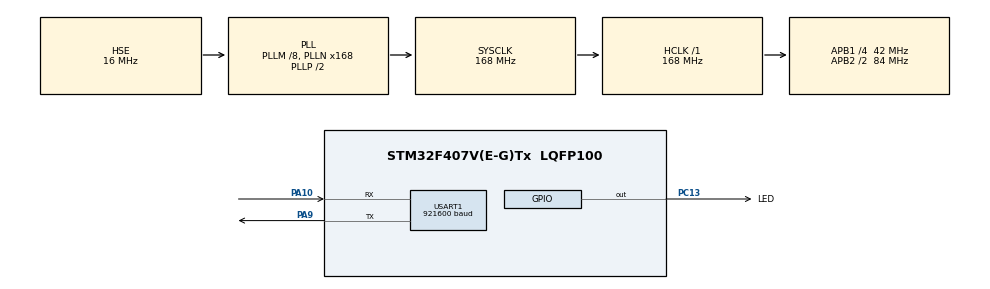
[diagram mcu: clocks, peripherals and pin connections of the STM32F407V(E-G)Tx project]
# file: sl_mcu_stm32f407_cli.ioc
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Dma.Request0=USART1_RX
Dma.Request1=USART1_TX
Dma.USART1_RX.0.Direction=DMA_PERIPH_TO_MEMORY
Dma.USART1_RX.0.FIFOMode=DMA_FIFOMODE_DISABLE
Dma.USART1_RX.0.Instance=DMA2_Stream2
Dma.USART1_RX.0.MemDataAlignment=DMA_MDATAALIGN_BYTE
Dma.USART1_RX.0.MemInc=DMA_MINC_ENABLE
Dma.USART1_RX.0.Mode=DMA_CIRCULAR
Dma.USART1_RX.0.PeriphDataAlignment=DMA_PDATAALIGN_BYTE
Dma.USART1_RX.0.PeriphInc=DMA_PINC_DISABLE
Dma.USART1_RX.0.Priority=DMA_PRIORITY_LOW
Dma.USART1_TX.1.Direction=DMA_MEMORY_TO_PERIPH
Dma.USART1_TX.1.FIFOMode=DMA_FIFOMODE_DISABLE
Dma.USART1_TX.1.Instance=DMA2_Stream7
Dma.USART1_TX.1.MemDataAlignment=DMA_MDATAALIGN_BYTE
Dma.USART1_TX.1.MemInc=DMA_MINC_ENABLE
Dma.USART1_TX.1.Mode=DMA_CIRCULAR
Dma.USART1_TX.1.PeriphDataAlignment=DMA_PDATAALIGN_BYTE
Dma.USART1_TX.1.PeriphInc=DMA_PINC_DISABLE
Dma.USART1_TX.1.Priority=DMA_PRIORITY_LOW
Mcu.Family=STM32F4
Mcu.Name=STM32F407V(E-G)Tx
Mcu.Package=LQFP100
NVIC.DMA2_Stream2_IRQn=true\:0\:0\:false\:false\:true\:false\:true\:true
NVIC.DMA2_Stream7_IRQn=true\:0\:0\:false\:false\:true\:false\:true\:true
NVIC.PriorityGroup=NVIC_PRIORITYGROUP_4
NVIC.USART1_IRQn=true\:0\:0\:false\:false\:true\:true\:true\:true
PA10.Mode=Asynchronous
PA10.Signal=USART1_RX
PA13.Mode=Trace_Asynchronous_SW
PA13.Signal=SYS_JTMS-SWDIO
PA14.Mode=Trace_Asynchronous_SW
PA14.Signal=SYS_JTCK-SWCLK
PA9.Mode=Asynchronous
PA9.Signal=USART1_TX
PB3.Mode=Trace_Asynchronous_SW
PB3.Signal=SYS_JTDO-SWO
PC13-ANTI_TAMP.GPIO_Label=LED
PC13-ANTI_TAMP.GPIO_ModeDefaultOutputPP=GPIO_MODE_OUTPUT_OD
PC13-ANTI_TAMP.GPIO_PuPd=GPIO_NOPULL
PC13-ANTI_TAMP.PinState=GPIO_PIN_SET
PC13-ANTI_TAMP.Signal=GPIO_Output
PH0-OSC_IN.Mode=HSE-External-Oscillator
PH0-OSC_IN.Signal=RCC_OSC_IN
PH1-OSC_OUT.Mode=HSE-External-Oscillator
PH1-OSC_OUT.Signal=RCC_OSC_OUT
ProjectManager.HeapSize=0x200
ProjectManager.StackSize=0x400
ProjectManager.TargetToolchain=STM32CubeIDE
RCC.48MHZClocksFreq_Value=48000000
RCC.AHBFreq_Value=168000000
RCC.APB1CLKDivider=RCC_HCLK_DIV4
RCC.APB1Freq_Value=42000000
RCC.APB1TimFreq_Value=84000000
RCC.APB2CLKDivider=RCC_HCLK_DIV2
RCC.APB2Freq_Value=84000000
RCC.APB2TimFreq_Value=168000000
RCC.CortexFreq_Value=168000000
RCC.HCLKFreq_Value=168000000
RCC.HSE_VALUE=16000000
RCC.HSI_VALUE=16000000
RCC.LSE_VALUE=32768
RCC.PLLM=8
RCC.PLLN=168
RCC.PLLQ=7
RCC.PLLSourceVirtual=RCC_PLLSOURCE_HSE
RCC.SYSCLKFreq_VALUE=168000000
RCC.SYSCLKSource=RCC_SYSCLKSOURCE_PLLCLK
RCC.VCOOutputFreq_Value=336000000
USART1.BaudRate=921600
USART1.OverSampling=UART_OVERSAMPLING_8
USART1.VirtualMode=VM_ASYNC
board=custom

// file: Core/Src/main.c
/* USER CODE BEGIN Header */
/**
 ******************************************************************************
 * @file           : main.c
 * @brief          : Main program body
 ******************************************************************************
 * @attention
 *
 * Copyright (c) 2026 STM32World <lth@stm32world.com>
 * All rights reserved.
 *
 * This software is licensed under terms that can be found in the LICENSE file
 * in the root directory of this software component.
 * If no LICENSE file comes with this software, it is provided AS-IS.
 *
 ******************************************************************************
 */
/* USER CODE END Header */
#include "main.h"

/* USER CODE BEGIN Includes */
#include <stdio.h>

// Just include the header here; DO NOT define EMBEDDED_CLI_IMPL here
#include "embedded_cli.h"
/* USER CODE END Includes */

/* USER CODE BEGIN PD */
#define RX_BUFFER_SIZE 128
/* USER CODE END PD */

UART_HandleTypeDef huart1;
DMA_HandleTypeDef hdma_usart1_rx;
DMA_HandleTypeDef hdma_usart1_tx;

/* USER CODE BEGIN PV */
EmbeddedCli *cli = NULL;
uint8_t rx_dma_buffer[RX_BUFFER_SIZE];
uint16_t old_pos = 0;
/* USER CODE END PV */

void SystemClock_Config(void);
static void MX_GPIO_Init(void);
static void MX_DMA_Init(void);
static void MX_USART1_UART_Init(void);
/* USER CODE BEGIN PFP */
void init_console(void);
void process_uart_dma_input(void);
/* USER CODE END PFP */

/* USER CODE BEGIN 0 */

// Send printf to uart1
int __io_putchar(int ch) {
    if (ch == '\n') {
        HAL_UART_Transmit(&huart1, (uint8_t*) "\r", 1, HAL_MAX_DELAY);
    }
    if (HAL_UART_Transmit(&huart1, (uint8_t*) &ch, 1, HAL_MAX_DELAY) != HAL_OK) {
        return -1;
    }
    return ch;
}

// 1. Provide a physical write wrapper (UART DMA / IT)
void write_char_cb(EmbeddedCli *cli, char c) {
    HAL_UART_Transmit(&huart1, (uint8_t*) &c, 1, HAL_MAX_DELAY);
}

// 2. Define a callback function for a command
void on_led_command(EmbeddedCli *cli, char *args, void *context) {
    HAL_GPIO_TogglePin(LED_GPIO_Port, LED_Pin);
    embeddedCliPrint(cli, "LED Toggled!\r\n");
}

void init_console(void) {
    // 3. Initialize CLI with default settings
    EmbeddedCliConfig *config = embeddedCliDefaultConfig();
    config->maxBindingCount = 16;
    cli = embeddedCliNew(config);
    if (cli == NULL) return;

    cli->writeChar = write_char_cb;

    // 4. Bind a command
    embeddedCliAddBinding(cli, (CliCommandBinding ) {
                    .name = "toggle-led",
                    .help = "Toggles the onboard LED",
                    .tokenizeArgs = false,
                    .context = NULL,
                    .binding = on_led_command
            });

    // 5. Start RX DMA & IDLE Line Interrupt
    __HAL_UART_ENABLE_IT(&huart1, UART_IT_IDLE);
    HAL_UART_Receive_DMA(&huart1, rx_dma_buffer, RX_BUFFER_SIZE);
}

// Read received bytes from DMA circular buffer
void process_uart_dma_input(void) {
    if (cli == NULL) return;

    uint16_t current_pos = RX_BUFFER_SIZE - __HAL_DMA_GET_COUNTER(&hdma_usart1_rx);

    if (current_pos != old_pos) {
        if (current_pos > old_pos) {
            for (uint16_t i = old_pos; i < current_pos; i++) {
                embeddedCliReceiveChar(cli, (char)rx_dma_buffer[i]);
            }
        } else {
            for (uint16_t i = old_pos; i < RX_BUFFER_SIZE; i++) {
                embeddedCliReceiveChar(cli, (char)rx_dma_buffer[i]);
            }
            for (uint16_t i = 0; i < current_pos; i++) {
                embeddedCliReceiveChar(cli, (char)rx_dma_buffer[i]);
            }
        }
        old_pos = current_pos;
    }
}

/* USER CODE END 0 */

int main(void)
{

    /* MCU Configuration--------------------------------------------------------*/

    /* Reset of all peripherals, Initializes the Flash interface and the Systick. */
    HAL_Init();

    /* Configure the system clock */
    SystemClock_Config();

    /* Initialize all configured peripherals */
    MX_GPIO_Init();
    MX_DMA_Init();
    MX_USART1_UART_Init();
    /* USER CODE BEGIN 2 */

    printf("\n\n\n--------\nStarting\n");

    init_console();

    /* USER CODE END 2 */

    /* Infinite loop */
    /* USER CODE BEGIN WHILE */

    register uint32_t now = 0, loop_cnt = 0, next_blink = 500, next_tick = 1000;

    while (1) {

        // Check DMA ring buffer for new input
        process_uart_dma_input();

        // Run inside your main while(1) loop (non-blocking)
        if (cli != NULL) {
            embeddedCliProcess(cli);
        }

//        now = uwTick;
//
//        if (now >= next_blink) {
//            HAL_GPIO_TogglePin(LED_GPIO_Port, LED_Pin);
//            next_blink += 500;
//        }

//        if (now >= next_tick) {
//
//            printf("Tick %lu (loop = %lu)\n", now / 1000, loop_cnt);
//
//            loop_cnt = 0;
//            next_tick = now + 1000;
//        }

        ++loop_cnt;

        /* USER CODE END WHILE */

    }
}

void SystemClock_Config(void)
{
    RCC_OscInitTypeDef RCC_OscInitStruct = { 0 };
    RCC_ClkInitTypeDef RCC_ClkInitStruct = { 0 };

    /** Configure the main internal regulator output voltage
     */
    __HAL_RCC_PWR_CLK_ENABLE();
    __HAL_PWR_VOLTAGESCALING_CONFIG(PWR_REGULATOR_VOLTAGE_SCALE1);

    /** Initializes the RCC Oscillators according to the specified parameters
     * in the RCC_OscInitTypeDef structure.
     */
    RCC_OscInitStruct.OscillatorType = RCC_OSCILLATORTYPE_HSE;
    RCC_OscInitStruct.HSEState = RCC_HSE_ON;
    RCC_OscInitStruct.PLL.PLLState = RCC_PLL_ON;
    RCC_OscInitStruct.PLL.PLLSource = RCC_PLLSOURCE_HSE;
    RCC_OscInitStruct.PLL.PLLM = 8;
    RCC_OscInitStruct.PLL.PLLN = 168;
    RCC_OscInitStruct.PLL.PLLP = RCC_PLLP_DIV2;
    RCC_OscInitStruct.PLL.PLLQ = 7;
    if (HAL_RCC_OscConfig(&RCC_OscInitStruct) != HAL_OK)
            {
        Error_Handler();
    }

    /** Initializes the CPU, AHB and APB buses clocks
     */
    RCC_ClkInitStruct.ClockType = RCC_CLOCKTYPE_HCLK | RCC_CLOCKTYPE_SYSCLK
            | RCC_CLOCKTYPE_PCLK1 | RCC_CLOCKTYPE_PCLK2;
    RCC_ClkInitStruct.SYSCLKSource = RCC_SYSCLKSOURCE_PLLCLK;
    RCC_ClkInitStruct.AHBCLKDivider = RCC_SYSCLK_DIV1;
    RCC_ClkInitStruct.APB1CLKDivider = RCC_HCLK_DIV4;
    RCC_ClkInitStruct.APB2CLKDivider = RCC_HCLK_DIV2;

    if (HAL_RCC_ClockConfig(&RCC_ClkInitStruct, FLASH_LATENCY_5) != HAL_OK)
            {
        Error_Handler();
    }
}

static void MX_USART1_UART_Init(void)
{

    huart1.Instance = USART1;
    huart1.Init.BaudRate = 921600;
    huart1.Init.WordLength = UART_WORDLENGTH_8B;
    huart1.Init.StopBits = UART_STOPBITS_1;
    huart1.Init.Parity = UART_PARITY_NONE;
    huart1.Init.Mode = UART_MODE_TX_RX;
    huart1.Init.HwFlowCtl = UART_HWCONTROL_NONE;
    huart1.Init.OverSampling = UART_OVERSAMPLING_8;
    if (HAL_UART_Init(&huart1) != HAL_OK)
            {
        Error_Handler();
    }

}

static void MX_DMA_Init(void)
{

    /* DMA controller clock enable */
    __HAL_RCC_DMA2_CLK_ENABLE();

    /* DMA interrupt init */
    /* DMA2_Stream2_IRQn interrupt configuration */
    HAL_NVIC_SetPriority(DMA2_Stream2_IRQn, 0, 0);
    HAL_NVIC_EnableIRQ(DMA2_Stream2_IRQn);
    /* DMA2_Stream7_IRQn interrupt configuration */
    HAL_NVIC_SetPriority(DMA2_Stream7_IRQn, 0, 0);
    HAL_NVIC_EnableIRQ(DMA2_Stream7_IRQn);

}

static void MX_GPIO_Init(void)
{
    GPIO_InitTypeDef GPIO_InitStruct = { 0 };

    /* GPIO Ports Clock Enable */
    __HAL_RCC_GPIOC_CLK_ENABLE();
    __HAL_RCC_GPIOH_CLK_ENABLE();
    __HAL_RCC_GPIOA_CLK_ENABLE();
    __HAL_RCC_GPIOB_CLK_ENABLE();

    /*Configure GPIO pin Output Level */
    HAL_GPIO_WritePin(LED_GPIO_Port, LED_Pin, GPIO_PIN_SET);

    /*Configure GPIO pin : LED_Pin */
    GPIO_InitStruct.Pin = LED_Pin;
    GPIO_InitStruct.Mode = GPIO_MODE_OUTPUT_OD;
    GPIO_InitStruct.Pull = GPIO_NOPULL;
    GPIO_InitStruct.Speed = GPIO_SPEED_FREQ_LOW;
    HAL_GPIO_Init(LED_GPIO_Port, &GPIO_InitStruct);

}

void Error_Handler(void)
{
    __disable_irq();
    while (1)
    {
    }
}
